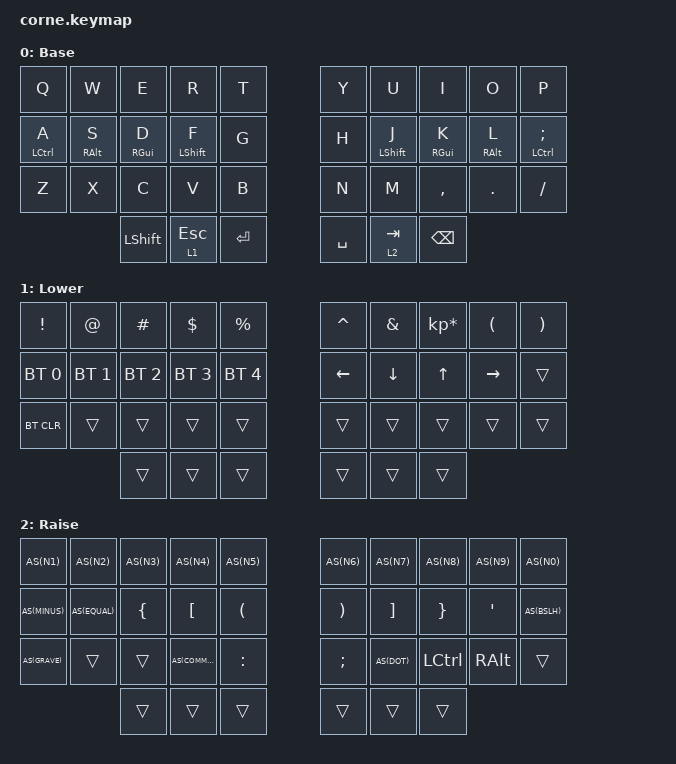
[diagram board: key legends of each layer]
/*
 * Copyright (c) 2020 The ZMK Contributors
 *
 * SPDX-License-Identifier: MIT
 */

#include <behaviors.dtsi>
#include <dt-bindings/zmk/keys.h>
#include <dt-bindings/zmk/bt.h>


#define AS(keycode) &as LS(keycode) keycode

&mt {
    flavor = "balanced";
    tapping-term-ms = <200>;
    quick-tap-ms = <175>;
    require-prior-idle-ms = <150>;
   };

/ {
    chosen {
        zmk,physical-layout = &foostan_corne_5col_layout;
    };

    behaviors {
        as: auto_shift {
            compatible = "zmk,behavior-hold-tap";
            #binding-cells = <2>;
            tapping_term_ms = <200>;
            quick_tap_ms = <0>;
            flavor = "tap-preferred";
            bindings = <&kp>, <&kp>;
        };
    };
        keymap {
                compatible = "zmk,keymap";

                default_layer {
// -----------------------------------------------------------------------------------------
// |  Q  |  W  |  E  |  R  |  T  |     |  Y  |  U   |  I   |  O   | P |
// |  A  |  S  |  D  |  F  |  G  |     |  H  |  J   |  K   |  L   | ' | 
// |  Z  |  X  |  C  |  V  |  B  |     |  N  |  M   | CTRL | META | . |
//             | GUI | LWR | SPC |     | ENT | RSE  | BSPC |
                        display-name = "Base";
                        bindings = <
   &kp Q       &kp W       &kp E      &kp R         &kp T         &kp Y     &kp U         &kp I      &kp O      &kp P
   &mt LCTL A  &mt RALT S  &mt RGUI D &mt LSHIFT F  &kp G         &kp H     &mt LSHIFT J  &mt RGUI K &mt RALT L &mt LCTL SEMICOLON
   &kp Z       &kp X       &kp C      &kp V         &kp B         &kp N     &kp M         &kp COMMA  &kp PERIOD &kp SLASH
                           &kp LSHIFT &lt 1 ESC     &kp RET       &kp SPACE &lt 2 TAB     &kp BSPC
                        >;
                };

                lower_layer {
// -----------------------------------------------------------------------------------------
// | !     |  @  |  #  |  $  |  %  |     |  ^  |  &  |  *  |  (  |  )  |
// | BT1   | BT2 | BT3 | BT4 | BT5 |     | LFT | DWN |  UP | RGT |     |
// | BTCLR |     |     |     |     |     |     |     |     |     |     |
//               | GUI |     | SPC |     | ENT | ESC | TAB |
                        display-name = "Lower";
                        bindings = <
   &kp EXCL     &kp AT       &kp HASH     &kp DLLR     &kp PRCNT        &kp CARET &kp AMPS  &kp KP_MULTIPLY &kp LPAR  &kp RPAR
   &bt BT_SEL 0 &bt BT_SEL 1 &bt BT_SEL 2 &bt BT_SEL 3 &bt BT_SEL 4     &kp LEFT  &kp DOWN  &kp UP          &kp RIGHT &trans 
   &bt BT_CLR   &trans       &trans       &trans       &trans           &trans    &trans    &trans          &trans    &trans 
                             &trans     &trans        &trans        &trans   &trans   &trans
                        >;
                };

                raise_layer {
// -----------------------------------------------------------------------------------------
// | 1! |  2@ |  3# |  4$ |  5% |     |  6^ |  7& |  8* |  9(  |  0)  |
// | -_ |  =+ |  {  |  [  |  (  |     |  )  |  ]  |  }  |  '"  |  \|  |
// | `~ |     |     |  ,< |  :  |     |  ;  |  .> | CTRL| META |      |
//            | GUI | ESC | SPC |     | ENT |     | TAB |
                        display-name = "Raise";
                        bindings = <

   AS(N1)    AS(N2)    AS(N3)    AS(N4)    AS(N5)        AS(N6)    AS(N7)    AS(N8)    AS(N9)   AS(N0)
   AS(MINUS) AS(EQUAL) &kp LBRC  &kp LBKT  &kp LPAR      &kp RPAR  &kp RBKT  &kp RBRC  &kp SQT  AS(BSLH)
   AS(GRAVE) &trans    &trans    AS(COMMA) &kp COLON     &kp SEMI  AS(DOT)   &kp LCTRL &kp RALT &trans
                       &trans &trans   &trans     &trans   &trans    &trans
                        >;
                };

                extra_1 {
                        status = "reserved";
                };

                extra_2 {
                        status = "reserved";
                };

                extra_3 {
                        status = "reserved";
                };
        };
};
